VERSION ""

NS_ :

BS_:

BU_: XXX

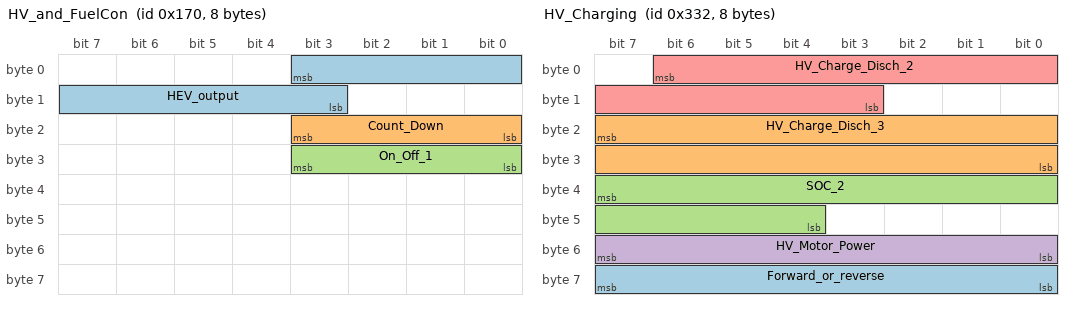
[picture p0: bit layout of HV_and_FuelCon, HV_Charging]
BO_ 368 HV_and_FuelCon: 8 XXX
 SG_ HEV_output : 3|9@0- (1,0) [0|281474976710655] "A_or_W" XXX
 SG_ Count_Down : 19|4@0+ (1,0) [0|65535] "Minutes" XXX
 SG_ On_Off_1 : 27|4@0+ (1,0) [0|255] "" XXX

BO_ 818 HV_Charging: 8 XXX
 SG_ Forward_or_reverse : 63|8@0+ (1,0) [0|255] "" XXX
 SG_ HV_Charge_Disch_3 : 23|16@0+ (1,-33000) [0|1048575] "A_or_W" XXX
 SG_ SOC_2 : 39|12@0+ (1,0) [0|255] "" XXX
 SG_ HV_Motor_Power : 55|8@0+ (1,0) [0|255] "" XXX
 SG_ HV_Charge_Disch_2 : 6|12@0- (1,-60) [0|65535] "A_or_W" XXX

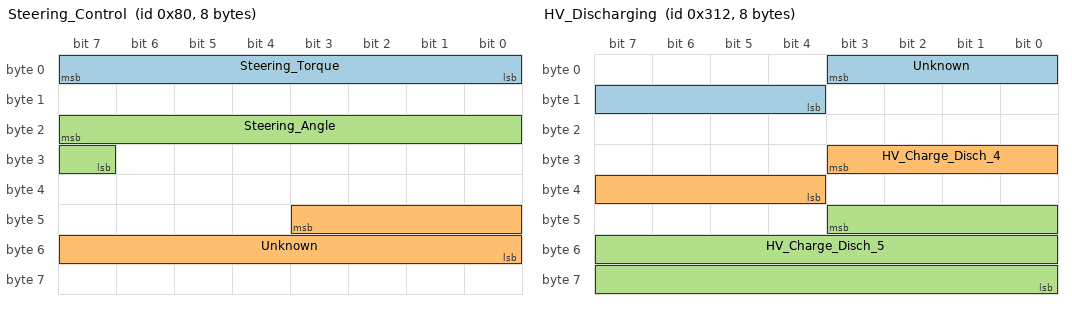
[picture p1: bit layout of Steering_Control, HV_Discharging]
BO_ 128 Steering_Control: 8 XXX
 SG_ Steering_Torque : 7|8@0- (1,-80) [0|18446744073709552000] "" XXX
 SG_ Unknown : 43|12@0+ (1,0) [0|16777215] "" XXX
 SG_ Steering_Angle : 23|9@0- (1,-160) [0|7] "" XXX

BO_ 768 NEW_MSG_1: 8 XXX
 SG_ NEW_SIGNAL_1 : 3|12@0+ (1,0) [0|255] "" XXX

BO_ 786 HV_Discharging: 8 XXX
 SG_ Unknown : 3|8@0+ (1,0) [0|255] "" XXX
 SG_ HV_Charge_Disch_4 : 27|8@0+ (1,0) [0|255] "" XXX
 SG_ HV_Charge_Disch_5 : 43|20@0+ (1,0) [0|16777215] "" XXX

CM_ SG_ 368 Count_Down "Countdown by one every minute";
CM_ SG_ 128 Steering_Angle "Negative clockwise";
